# dcan_secure register map
Vendor: Texas Instruments
Registers are 32-bit, access per field, reset 0x0 unless marked. A register's access mark holds for its fields unless they carry their own. Offsets are as the file gives them; [hi:lo] are bit positions; {n}, {i} and the like mark numbered series; 'fields as' and 'values as' point back to an identical list; <NAME> marks a mode.

## dcan_secure (part 2 of 2)
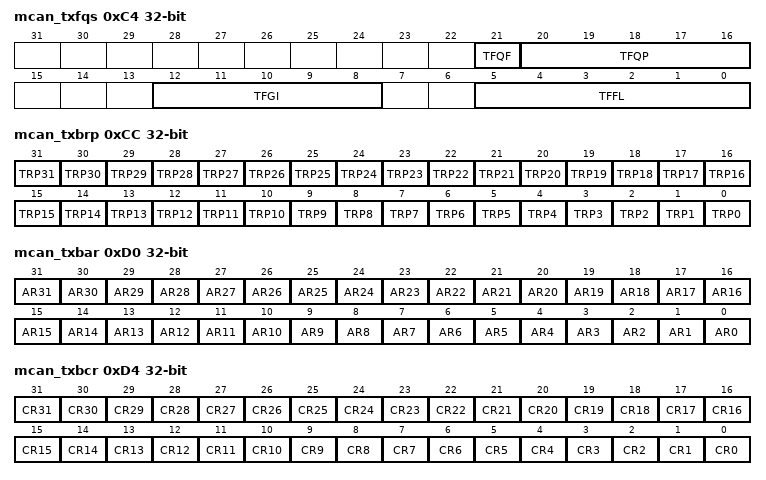
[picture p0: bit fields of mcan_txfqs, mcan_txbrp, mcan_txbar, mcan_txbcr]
0xC4 mcan_txfqs ro — The Tx FIFO/Queue status is related to the pending Tx requests listed in register TXBRP. Therefore the effect of Add/Cancellation requests may be delayed due to a running Tx scan (TXBRP not yet updated).
  [21] TFQF — Tx FIFO/Queue Full 0 Tx FIFO/Queue not full 1 Tx FIFO/Queue full
  [20:16] TFQP — Tx FIFO/Queue Put Index. Tx FIFO/Queue write index pointer, range 0 to 31. Note: In case of mixed configurations where dedicated Tx Buffers are combined with a Tx FIFO or a Tx Queue, the Put and Get Indices indicate the number of the Tx Buffer starting with the first dedicated Tx Buffers. Example: For a configuration of 12 dedicated Tx Buffers and a Tx FIFO of 20 Buffers a Put Index of 15 points to the fourth buffer of the Tx FIFO.
  [12:8] TFGI — Tx FIFO Get Index. Tx FIFO read index pointer, range 0 to 31. Read as zero when Tx Queue operation is configured (TXBC.TFQM = '1'). Note: In case of mixed configurations where dedicated Tx Buffers are combined with a Tx FIFO or a Tx Queue, the Put and Get Indices indicate the number of the Tx Buffer starting with the first dedicated Tx Buffers. Example: For a configuration of 12 dedicated Tx Buffers and a Tx FIFO of 20 Buffers a Put Index of 15 points to the fourth buffer of the Tx FIFO.
  [5:0] TFFL — Tx FIFO Free Level. Number of consecutive free Tx FIFO elements starting from TFGI, range 0 to 32. Read as zero when Tx Queue operation is configured (TXBC.TFQM = '1').
0xC8 mcan_txesc — Configures the number of data bytes belonging to a Tx Buffer element. Data field sizes > 8 bytes are intended for CAN FD operation only.
  [2:0] TBDS rw — Tx Buffer Data Field Size 000 8 byte data field 001 12 byte data field 010 16 byte data field 011 20 byte data field 100 24 byte data field 101 32 byte data field 110 48 byte data field 111 64 byte data field Note: In case the data length code DLC of a Tx Buffer element is configured to a value higher than the Tx Buffer data field size TXESC.TBDS, the bytes not defined by the Tx Buffer are transmitted as "0xCC" (padding bytes). Qualified Write is possible only with CCCR.CCE='1' and CCCR.INIT='1'.
0xCC mcan_txbrp ro — MCAN Tx Buffer Request Pending
  [n] TRP{n} (n=1..31) — Transmission Request Pending {n}. See description for bit 0.
  [0] TRP0 — Transmission Request Pending 0. Each Tx Buffer has its own Transmission Request Pending bit. The bits are set via register TXBAR. The bits are reset after a requested transmission has completed or has been cancelled via register TXBCR. TXBRP bits are set only for those Tx Buffers configured via TXBC. After a TXBRP bit has been set, a Tx scan is started to check for the pending Tx request with the highest priority (Tx Buffer with lowest Message ID). A cancellation request resets the corresponding transmission request pending bit of register TXBRP. In case a transmission has already been started when a cancellation is requested, this is done at the end of the transmission, regardless whether the transmission was successful or not. The cancellation request bits are reset directly after the corresponding TXBRP bit has been reset. After a cancellation has been requested, a finished cancellation is signalled via TXBCF - after successful transmission together with the corresponding TXBTO bit - when the transmission has not yet been started at the point of cancellation - when the transmission has been aborted due to lost arbitration - when an error occurred during frame transmission In DAR mode all transmissions are automatically cancelled if they are not successful. The corresponding TXBCF bit is set for all unsuccessful transmissions. 0 No transmission request pending 1 Transmission request pending Note: TXBRP bits which are set while a Tx scan is in progress are not considered during this particular Tx scan. In case a cancellation is requested for such a Tx Buffer, this Add Request is cancelled immediately, the corresponding TXBRP bit is reset.
0xD0 mcan_txbar rw — MCAN Tx Buffer Add Request
  [n] AR{n} (n=1..31) — Add Request {n}. See description for bit 0.
  [0] AR0 — Add Request 0. Each Tx Buffer has its own Add Request bit. Writing a '1' will set the corresponding Add Request bit; writing a '0' has no impact. This enables the Host to set transmission requests for multiple Tx Buffers with one write to TXBAR. TXBAR bits are set only for those Tx Buffers configured via TXBC. When no Tx scan is running, the bits are reset immediately, else the bits remain set until the Tx scan process has completed. 0 No transmission request added 1 Transmission requested added Note: If an add request is applied for a Tx Buffer with pending transmission request (corresponding TXBRP bit already set), this add request is ignored. Qualified Write is possible only with CCCR.CCE='0'
0xD4 mcan_txbcr rw — MCAN Tx Buffer Cancellation Request
  [n] CR{n} (n=1..31) — Cancellation Request {n}. See description for bit 0.
  [0] CR0 — Cancellation Request 0. Each Tx Buffer has its own Cancellation Request bit. Writing a '1' will set the corresponding Cancellation Request bit; writing a '0' has no impact. This enables the Host to set cancellation requests for multiple Tx Buffers with one write to TXBCR. TXBCR bits are set only for those Tx Buffers configured via TXBC. The bits remain set until the corresponding bit of TXBRP is reset. 0 No cancellation pending 1 Cancellation pending Qualified Write is possible only with CCCR.CCE='0'
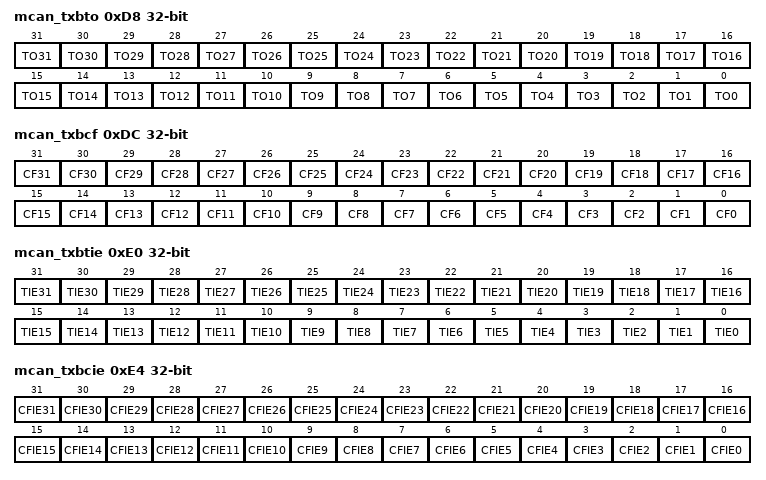
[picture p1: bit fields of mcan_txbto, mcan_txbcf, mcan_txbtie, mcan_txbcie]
0xD8 mcan_txbto ro — MCAN Tx Buffer Transmission Occurred
  [n] TO{n} (n=1..31) — Transmission Occurred {n}. See description for bit 0.
  [0] TO0 — Transmission Occurred 0. Each Tx Buffer has its own Transmission Occurred bit. The bits are set when the corresponding TXBRP bit is cleared after a successful transmission. The bits are reset when a new transmission is requested by writing a '1' to the corresponding bit of register TXBAR. 0 No transmission occurred 1 Transmission occurred
0xDC mcan_txbcf ro — MCAN Tx Buffer Cancellation Finished
  [n] CF{n} (n=1..31) — Cancellation Finished {n}. See description for bit 0.
  [0] CF0 — Cancellation Finished 0. Each Tx Buffer has its own Cancellation Finished bit. The bits are set when the corresponding TXBRP bit is cleared after a cancellation was requested via TXBCR. In case the corresponding TXBRP bit was not set at the point of cancellation, CF is set immediately. The bits are reset when a new transmission is requested by writing a '1' to the corresponding bit of register TXBAR. 0 No transmit buffer cancellation 1 Transmit buffer cancellation finished
0xE0 mcan_txbtie rw — MCAN Tx Buffer Transmission Interrupt Enable
  [n] TIE{n} (n=0..31) — Transmission Interrupt Enable {n}. Each Tx Buffer has its own Transmission Interrupt Enable bit. 0 Transmission interrupt disabled 1 Transmission interrupt enable
0xE4 mcan_txbcie rw — MCAN Tx Buffer Cancellation Finished Interrupt Enable
  [n] CFIE{n} (n=0..31) — Cancellation Finished Interrupt Enable {n}. Each Tx Buffer has its own Cancellation Finished Interrupt Enable bit. 0 Cancellation finished interrupt disabled 1 Cancellation finished interrupt enabled
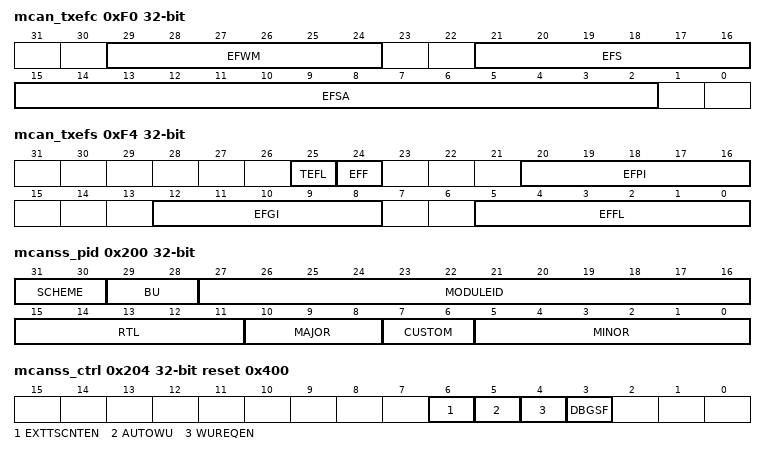
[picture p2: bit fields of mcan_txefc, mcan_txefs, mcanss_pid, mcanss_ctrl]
0xF0 mcan_txefc — MCAN Tx Event FIFO Configuration
  [29:24] EFWM rw — Event FIFO Watermark 0 Watermark interrupt disabled 1-32 Level for Tx Event FIFO watermark interrupt (IR.TEFW) >32 Watermark interrupt disabled
  [21:16] EFS rw — Event FIFO Size. The Tx Event FIFO elements are indexed from 0 to EFS - 1. 0 Tx Event FIFO disabled 1-32 Number of Tx Event FIFO elements >32 Values greater than 32 are interpreted as 32
  [15:2] EFSA rw — Event FIFO Start Address. Start address of Tx Event FIFO in Message RAM (32-bit word address).
0xF4 mcan_txefs ro — MCAN Tx Event FIFO Status
  [25] TEFL — Tx Event FIFO Element Lost. This bit is a copy of interrupt flag IR.TEFL. When IR.TEFL is reset, this bit is also reset. 0 No Tx Event FIFO element lost 1 Tx Event FIFO element lost, also set after write attempt to Tx Event FIFO of size zero.
  [24] EFF — Event FIFO Full 0 Tx Event FIFO not full 1 Tx Event FIFO full
  [20:16] EFPI — Event FIFO Put Index.Tx Event FIFO write index pointer, range 0 to 31.
  [12:8] EFGI — Event FIFO Get Index. Tx Event FIFO read index pointer, range 0 to 31.
  [5:0] EFFL — Event FIFO Fill Level. Number of elements stored in Tx Event FIFO, range 0 to 32.
0xF8 mcan_txefa — MCAN Tx Event FIFO Acknowledge
  [4:0] EFAI rw — Event FIFO Acknowledge Index. After the Host has read an element or a sequence of elements from the Tx Event FIFO it has to write the index of the last element read from Tx Event FIFO to EFAI. This will set the Tx Event FIFO Get Index TXEFS.EFGI to EFAI + 1 and update the Event FIFO Fill Level TXEFS.EFFL.
0x200 mcanss_pid ro reset not defined — MCAN Subsystem Revision Register
  [31:30] SCHEME — PID Register Scheme
  [29:28] BU — Business Unit: 0x2 = Processors
  [27:16] MODULEID — Module Identification Number
  [15:11] RTL — RTL revision. Will vary depending on release
  [10:8] MAJOR — Major Revision of the MCAN Subsystem
  [7:6] CUSTOM — Custom Value
  [5:0] MINOR — Minor Revision of the MCAN Subsystem
0x204 mcanss_ctrl reset 0x400 (reset mask 0xFFFFFF80) — MCAN Subsystem Control Register
  [6] EXTTSCNTEN rw — External Timestamp Counter Enable. 0 External timestamp counter disabled 1 External timestamp counter enabled
  [5] AUTOWU rw — Automatic Wakeup Enable. Enables the MCANSS to automatically clear the MCAN CCCR.INIT bit, fully waking the MCAN up, on an enabled wakeup request. 0 Disable the automatic write to CCCR.INIT 1 Enable the automatic write to CCCR.INIT
  [4] WUREQEN rw — Wakeup Request Enable. Enables the MCANSS to wakeup on CAN RXD activity. 0 Disable wakeup request 1 Enables wakeup request
  [3] DBGSF rw — Debug Suspend Free Bit. Enables debug suspend. 0 Disable debug suspend 1 Enable debug suspend
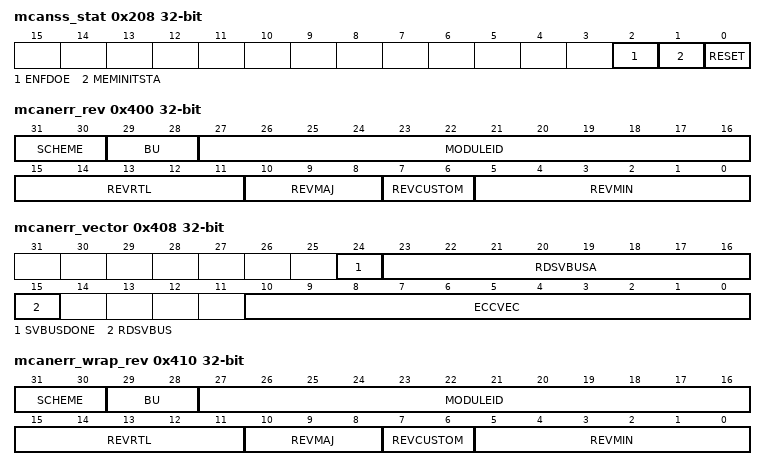
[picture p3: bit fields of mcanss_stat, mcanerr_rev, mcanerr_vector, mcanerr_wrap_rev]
0x208 mcanss_stat ro — MCAN Subsystem Status Register
  [2] ENFDOE — Flexible Datarate Operation Enable. Determines whether CAN FD operation may be enabled via the MCAN core CCCR.FDOE bit (bit 8) or if only standard CAN operation is possible with this instance of the MCAN. 0 MCAN is only capable of standard CAN communication 1 MCAN may be configured to perform CAN FD communication
  [1] MEMINITSTA — Memory Initialization Done. 0 Message RAM initialization is in progress 1 Message RAM is initialized for use
  [0] RESET — Soft Reset Status. 0 Not in reset 1 Reset is in progress
0x20C mcanss_ics — MCAN Subsystem Interrupt Clear Shadow Register
  [0] TSCNTOVFL rw — External Timestamp Counter Overflow Interrupt Status Clear. Reads always return a 0. 0 Write of '0' has no effect 1 Write of '1' clears the MCANSS_IRS.EXT_TS_CNTR_OVFL bit
0x210 mcanss_irs — MCAN Subsystem Interrupt Raw Status Register
  [0] TSCNTOVFL rw — External Timestamp Counter Overflow Interrupt Status. This bit is set by HW or by a SW write of '1'. To clear, use the MCANSS_ICS.EXT_TS_CNTR_OVFL bit. 0 External timestamp counter has not overflowed 1 External timestamp counter has overflowed When this bit is set to '1' by HW or SW, the MCANSS_EXT_TS_UNSERVICED_INTR_CNTR.EXT_TS_INTR_CNTR bit field will increment by 1.
0x214 mcanss_iecs — MCAN Subsystem Interrupt Enable Clear Shadow Register
  [0] TSCNTOVFL rw — External Timestamp Counter Overflow Interrupt Enable Clear. Reads always return a 0. 0 Write of '0' has no effect 1 Write of '1' clears the MCANSS_IES.EXT_TS_CNTR_OVFL bit
0x218 mcanss_ie — MCAN Subsystem Interrupt Enable Register
  [0] TSCNTOVFL rw — External Timestamp Counter Overflow Interrupt Enable. A write of '0' has no effect. A write of '1' sets the MCANSS_IES.EXT_TS_CNTR_OVFL bit.
0x21C mcanss_ies ro — MCAN Subsystem Masked Interrupt Status. It is the logical AND of IRS and IE for the respective bits.
  [0] TSCNTOVFL — External Timestamp Counter Overflow masked interrupt status. 0 External timestamp counter overflow interrupt is cleared 1 External timestamp counter overflow interrupt is set
0x220 mcanss_eoi — MCAN Subsystem End of Interrupt
  [7:0] EOI rw — End of Interrupt. A write to this register will clear the associated interrupt. If the unserviced interrupt counter is > 1, another interrupt is generated. 0x00 External TS Interrupt is cleared 0x01 MCAN(0) interrupt is cleared 0x02 MCAN(1) interrupt is cleared Other writes are ignored.
0x224 mcanss_ext_ts_prescaler — MCAN Subsystem External Timestamp Prescaler 0
  [23:0] PRESCALER rw — External Timestamp Prescaler Reload Value. The external timestamp count rate is the host (system) clock rate divided by this value, except in the case of 0. A zero value in this bit field will act identically to a value of 0x000001.
0x228 mcanss_ext_ts_unserviced_intr_cntr ro — MCAN Subsystem External Timestamp Unserviced Interrupts Counter
  [4:0] INTRCNT — External Timestamp Counter Unserviced Rollover Interrupts. If this value is > 1, an MCANSS_EOI write of '1' to bit 0 will issue another interrupt. The status of this bit field is affected by the MCANSS_IRS.EXT_TS_CNTR_OVFL bit field.
0x400 mcanerr_rev ro reset not defined — MCAN Error Aggregator Revision Register
  [31:30] SCHEME — PID Register Scheme
  [29:28] BU — Business Unit: 0x2 = Processors
  [27:16] MODULEID — Module Identification Number
  [15:11] REVRTL — RTL revision. Will vary depending on release
  [10:8] REVMAJ — Major Revision of the Error Aggregator
  [7:6] REVCUSTOM — Custom Revision of the Error Aggregator
  [5:0] REVMIN — Minor Revision of the Error Aggregator
0x408 mcanerr_vector — Each error detection and correction (EDC) controller has a bank of error registers (offsets 0x10 - 0x3B) associated with it. These registers are accessed via an internal serial bus (SVBUS). To access them through the ECC aggregator the controller ID desired must be written to the ECC_VECTOR field, together with the RD_SVBUS trigger and RD_SVBUS_ADDRESS bit field. This initiates the serial read which consummates by setting the RD_SVBUS_DONE bit. At this point the addressed register may be read by a normal CPU read of the appropriate offset address.
  [24] SVBUSDONE ro — Read Completion Flag
  [23:16] RDSVBUSA rw — Read Address Offset
  [15] RDSVBUS rw — Read Trigger
  [10:0] ECCVEC rw — ECC RAM ID. Each error detection and correction (EDC) controller has a bank of error registers (offsets 0x10 - 0x3B) associated with it. These registers are accessed via an internal serial bus (SVBUS). To access them through the ECC aggregator the controller ID desired must be written to the ECC_VECTOR field, together with the RD_SVBUS trigger and RD_SVBUS_ADDRESS bit field. This initiates the serial read which consummates by setting the RD_SVBUS_DONE bit. At this point the addressed register may be read by a normal CPU read of the appropriate offset address. 0x000 Message RAM ECC controller is selected Others Reserved (do not use) Subsequent writes through the SVBUS (offsets 0x10 - 0x3B) have a delayed completion. To avoid conflicts, perform a read back of a register within this range after writing.
0x40C mcanerr_stat ro reset 0x1002 — MCAN Error Misc Status
  [10:0] NUMRAMS — Number of RAMs. Number of ECC RAMs serviced by the aggregator.
0x410 mcanerr_wrap_rev ro reset not defined — This register is accessed through the ECC aggregator via an internal serial bus. To access, the appropriate procedure must be first followed in the MCAN ECC Vector Register.
  fields as mcanerr_rev
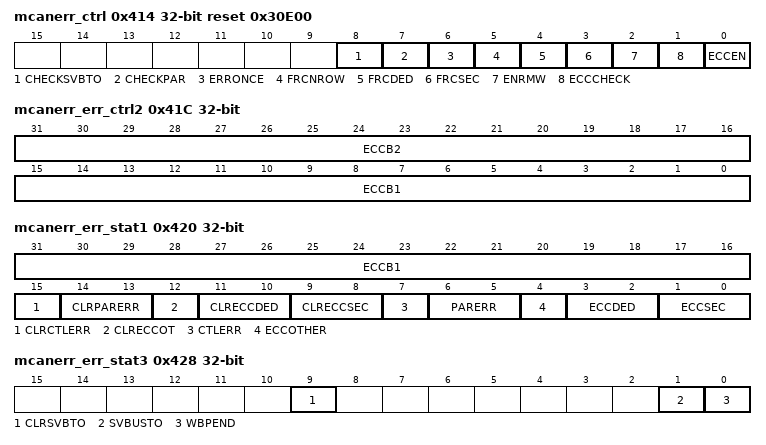
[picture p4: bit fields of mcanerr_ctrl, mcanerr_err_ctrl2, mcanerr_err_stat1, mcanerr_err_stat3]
0x414 mcanerr_ctrl reset 0x30E00 (reset mask 0xFFFFFE00) — This register is accessed through the ECC aggregator via an internal serial bus. To access, the appropriate procedure must be first followed in the MCAN ECC Vector Register.
  [8] CHECKSVBTO rw — Enables Serial VBUS timeout mechanism
  [7] CHECKPAR rw — Enables parity checking on internal data
  [6] ERRONCE rw — If this bit is set, the FORCE_SEC/FORCE_DED will inject an error to the specified row only once. The FORCE_SEC bit will be cleared once a writeback happens. If writeback is not enabled, this error will be cleared the cycle following the read when the data is corrected. For double-bit errors, the FORCE_DED bit will be cleared the cycle following the double-bit error. Any subsequent reads will not force an error.
  [5] FRCNROW rw — Enable single/double-bit error on the next RAM read, regardless of the MCANERR_ERR_CTRL1.ECC_ROW setting. For write through mode, this applies to writes as well as reads.
  [4] FRCDED rw — Force double-bit error. Cleared the cycle following the error if ERROR_ONCE is asserted. For write through mode, this applies to writes as well as reads. MCANERR_ERR_CTRL1 and MCANERR_ERR_CTRL2 should be configured prior to setting this bit.
  [3] FRCSEC rw — Force single-bit error. Cleared on a writeback or the cycle following the error if ERROR_ONCE is asserted. For write through mode, this applies to writes as well as reads. MCANERR_ERR_CTRL1 and MCANERR_ERR_CTRL2 should be configured prior to setting this bit.
  [2] ENRMW rw — Enable read-modify-write on partial word writes
  [1] ECCCHECK rw — Enable ECC Check. ECC is completely bypassed if both ECC_ENABLE and ECC_CHECK are '0'.
  [0] ECCEN rw — Enable ECC Generation
0x418 mcanerr_err_ctrl1 rw — This register is accessed through the ECC aggregator via an internal serial bus. To access, the appropriate procedure must be first followed in the MCAN ECC Vector Register.
  [31:0] ECCROW — Row address where FORCE_SEC or FORCE_DED needs to be applied. This is ignored if FORCE_N_ROW is set.
0x41C mcanerr_err_ctrl2 rw — This register is accessed through the ECC aggregator via an internal serial bus. To access, the appropriate procedure must be first followed in the MCAN ECC Vector Register.
  [31:16] ECCB2 — Second column/data bit that needs to be flipped when FORCE_DED is set
  [15:0] ECCB1 — Column/Data bit that needs to be flipped when FORCE_SEC or FORCE_DED is set
0x420 mcanerr_err_stat1 — This register is accessed through the ECC aggregator via an internal serial bus. To access, the appropriate procedure must be first followed in the MCAN ECC Vector Register.
  [31:16] ECCB1 ro — ECC Error Bit Position. Indicates the bit position in the RAM data that is in error on an SEC error. Only valid on an SEC error. 0 Bit 0 is in error 1 Bit 1 is in error 2 Bit 2 is in error 3 Bit 3 is in error ... 31 Bit 31 is in error >32 Invalid
  [15] CLRCTLERR rw — Writing a '1' clears the CTRL_REG_ERROR bit
  [14:13] CLRPARERR rw — Clear Parity Error. A write of a non-zero value to this bit field decrements the PARITY_ERROR bit field by the value provided.
  [12] CLRECCOT rw — Writing a '1' clears the ECC_OTHER bit.
  [11:10] CLRECCDED rw — Clear ECC_DED. A write of a non-zero value to this bit field decrements the ECC_DED bit field by the value provided.
  [9:8] CLRECCSEC rw — Clear ECC_SEC. A write of a non-zero value to this bit field decrements the ECC_SEC bit field by the value provided.
  [7] CTLERR rw — Control Register Error. A bit field in the control register is in an ambiguous state. This means that the redundancy registers have detected a state where not all values are the same and has defaulted to the reset state. S/W needs to re-write these registers to a known state. A write of 1 will set this interrupt flag.
  [6:5] PARERR rw — Parity Error Status. A 2-bit saturating counter of the number of parity errors that have occurred since last cleared. 0 No parity error detected 1 One parity error was detected 2 Two parity errors were detected 3 Three parity errors were detected A write of a non-zero value to this bit field increments it by the value provided.
  [4] ECCOTHER rw — SEC While Writeback Error Status 0 No SEC error while writeback pending 1 Indicates that successive single-bit errors have occurred while a writeback is still pending
  [3:2] ECCDED rw — Double Bit Error Detected Status. A 2-bit saturating counter of the number of DED errors that have occurred since last cleared. 0 No double-bit error detected 1 One double-bit error was detected 2 Two double-bit errors were detected 3 Three double-bit errors were detected A write of a non-zero value to this bit field increments it by the value provided.
  [1:0] ECCSEC rw — Single Bit Error Corrected Status. A 2-bit saturating counter of the number of SEC errors that have occurred since last cleared. 0 No single-bit error detected 1 One single-bit error was detected and corrected 2 Two single-bit errors were detected and corrected 3 Three single-bit errors were detected and corrected A write of a non-zero value to this bit field increments it by the value provided.
0x424 mcanerr_err_stat2 ro — This register is accessed through the ECC aggregator via an internal serial bus. To access, the appropriate procedure must be first followed in the MCAN ECC Vector Register.
  [31:0] ECCROW — Indicates the row address where the single or double-bit error occurred. This value is address offset/4.
0x428 mcanerr_err_stat3 — This register is accessed through the ECC aggregator via an internal serial bus. To access, the appropriate procedure must be first followed in the MCAN ECC Vector Register.
  [9] CLRSVBTO rw — Write 1 to clear the Serial VBUS Timeout Flag
  [1] SVBUSTO rw — Serial VBUS Timeout Flag. Write 1 to set.
  [0] WBPEND ro — Delayed Write Back Pending Status 0 No write back pending 1 An ECC data correction write back is pending
0x43C mcanerr_sec_eoi — MCAN Single Error Corrected End of Interrupt Register
  [0] EOIWR rw — Write to this register indicates that software has acknowledged the pending interrupt and the next interrupt can be sent to the host. Note that a write to the MCANERR_ERR_STAT1.CLR_ECC_SEC goes through the SVBUS and has a delayed completion. To avoid an additional interrupt, read the MCANERR_ERR_STAT1 register back prior to writing to this bit field.
0x440 mcanerr_sec_status — MCAN Single Error Corrected Interrupt Status Register
  [0] MGSPEND rw — Message RAM SEC Interrupt Pending 0 No SEC interrupt is pending 1 SEC interrupt is pending
0x480 mcanerr_sec_enable_set — MCAN Single Error Corrected Interrupt Enable Set Register
  [0] MSGENSET rw — Message RAM SEC Interrupt Pending Enable Set. Writing a 1 to this bit enables the Message RAM SEC error interrupts. Writing a 0 has no effect. Reads return the corresponding enable bit's current value.
0x4C0 mcanerr_sec_enable_clr — MCAN Single Error Corrected Interrupt Enable Clear Register
  [0] MSGENCLR rw — Message RAM SEC Interrupt Pending Enable Clear. Writing a 1 to this bit disables the Message RAM SEC error interrupts. Writing a 0 has no effect. Reads return the corresponding enable bit's current value.
0x53C mcanerr_ded_eoi — MCAN Double Error Detected End of Interrupt Register
  [0] EOIWR rw — Write to this register indicates that software has acknowledged the pending interrupt and the next interrupt can be sent to the host. Note that a write to the MCANERR_ERR_STAT1.CLR_ECC_DED goes through the SVBUS and has a delayed completion. To avoid an additional interrupt, read the MCANERR_ERR_STAT1 register back prior to writing to this bit field.
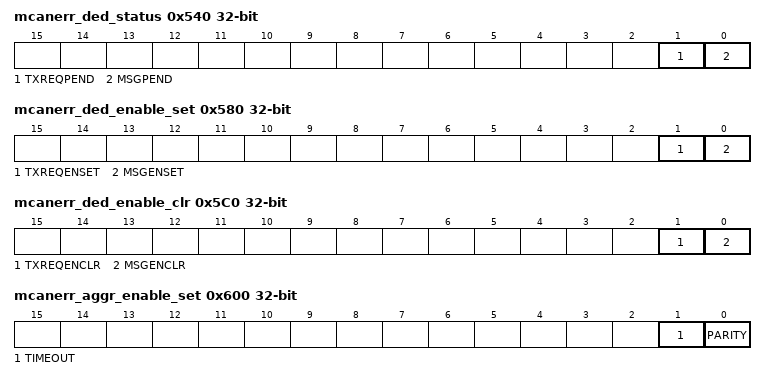
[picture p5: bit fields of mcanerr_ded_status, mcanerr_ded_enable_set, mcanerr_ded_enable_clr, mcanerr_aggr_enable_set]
0x540 mcanerr_ded_status — MCAN Double Error Detected Interrupt Status Register
  [1] TXREQPEND rw — TX Empty DMA Request Parity Interrupt Pending 0 No parity error interrupt is pending 1 A parity error interrupt is pending
  [0] MSGPEND rw — Message RAM DED Interrupt Pending 0 No DED interrupt is pending 1 DED interrupt is pending
0x580 mcanerr_ded_enable_set — MCAN Double Error Detected Interrupt Enable Set Register
  [1] TXREQENSET rw — TX Empty DMA Request Parity Interrupt Pending Enable Set. Writing a 1 to this bit enables the TX empty DMA request parity error interrupts. Writing a 0 has no effect. Reads return the corresponding enable bit's current value.
  [0] MSGENSET rw — Message RAM DED Interrupt Pending Enable Set. Writing a 1 to this bit enables the Message RAM DED error interrupts. Writing a 0 has no effect. Reads return the corresponding enable bit's current value.
0x5C0 mcanerr_ded_enable_clr — MCAN Double Error Detected Interrupt Enable Clear Register
  [1] TXREQENCLR rw — TX Empty DMA Request Parity Interrupt Pending Enable Clear. Writing a 1 to this bit disables the TX empty DMA request parity error interrupts. Writing a 0 has no effect. Reads return the corresponding enable bit's current value.
  [0] MSGENCLR rw — Message RAM DED Interrupt Pending Enable Clear. Writing a 1 to this bit disables the Message RAM DED error interrupts. Writing a 0 has no effect. Reads return the corresponding enable bit's current value.
0x600 mcanerr_aggr_enable_set — MCAN Error Aggregator Enable Set Register
  [1] TIMEOUT rw — Write 1 to enable timeout errors. Reads return the corresponding enable bit's current value.
  [0] PARITY rw — Write 1 to enable parity errors. Reads return the corresponding enable bit's current value.
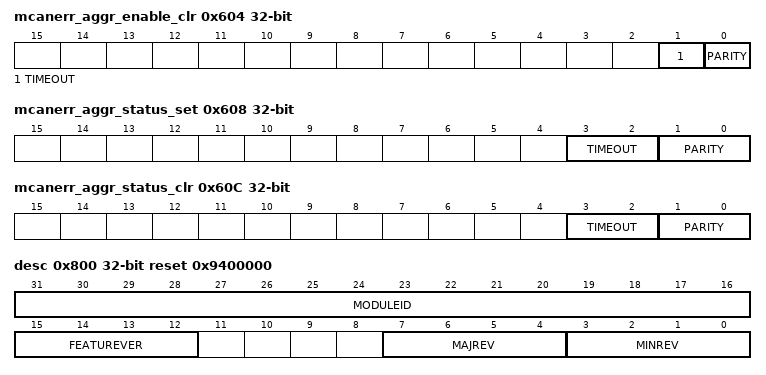
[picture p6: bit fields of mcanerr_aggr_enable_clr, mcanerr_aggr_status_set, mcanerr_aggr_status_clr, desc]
0x604 mcanerr_aggr_enable_clr — MCAN Error Aggregator Enable Clear Register
  [1] TIMEOUT rw — Write 1 to disable timeout errors. Reads return the corresponding enable bit's current value.
  [0] PARITY rw — Write 1 to disable parity errors. Reads return the corresponding enable bit's current value.
0x608 mcanerr_aggr_status_set — MCAN Error Aggregator Status Set Register
  [3:2] TIMEOUT rw — Aggregator Serial VBUS Timeout Error Status 2-bit saturating counter of the number of SVBUS timeout errors that have occurred since last cleared. 0 No timeout errors have occurred 1 One timeout error has occurred 2 Two timeout errors have occurred 3 Three timeout errors have occurred A write of a non-zero value to this bit field increments it by the value provided.
  [1:0] PARITY rw — Aggregator Parity Error Status 2-bit saturating counter of the number of parity errors that have occurred since last cleared. 0 No parity errors have occurred 1 One parity error has occurred 2 Two parity errors have occurred 3 Three parity errors have occurred A write of a non-zero value to this bit field increments it by the value provided.
0x60C mcanerr_aggr_status_clr — MCAN Error Aggregator Status Clear Register
  [3:2] TIMEOUT rw — Aggregator Serial VBUS Timeout Error Status 2-bit saturating counter of the number of SVBUS timeout errors that have occurred since last cleared. 0 No timeout errors have occurred 1 One timeout error has occurred 2 Two timeout errors have occurred 3 Three timeout errors have occurred A write of a non-zero value to this bit field decrements it by the value provided.
  [1:0] PARITY rw — Aggregator Parity Error Status 2-bit saturating counter of the number of parity errors that have occurred since last cleared. 0 No parity errors have occurred 1 One parity error has occurred 2 Two parity errors have occurred 3 Three parity errors have occurred A write of a non-zero value to this bit field decrements it by the value provided.
0x800 desc ro reset 0x9400000 — This register identifies the peripheral and its exact version.
  [31:16] MODULEID — Module identification contains a unique peripheral identification number. The assignments are maintained in a central database for all of the platform modules to ensure uniqueness.
    0=MINIMUM (Smallest value); 0xFFFF=MAXIMUM (Highest possible value)
  [15:12] FEATUREVER — Feature Set for the module *instance*
    0=VERSION_0 (MCAN module with CAN-FD mode enabled <<Internal Note: This is an in-IP paper spin variant. How does this map to the SYS_MCAN_ENABLE_FD choice value?>>); 1=VERSION_1 (MCAN module with CAN-FD mode disabled <<Internal Note: This is an in-IP paper spin variant. How does this map to the SYS_MCAN_ENABLE_FD choice value?>>)
  [7:4] MAJREV — Major rev of the IP
    0=MINIMUM (Smallest value); 15=MAXIMUM (Highest possible value)
  [3:0] MINREV — Minor rev of the IP
    values as MAJREV
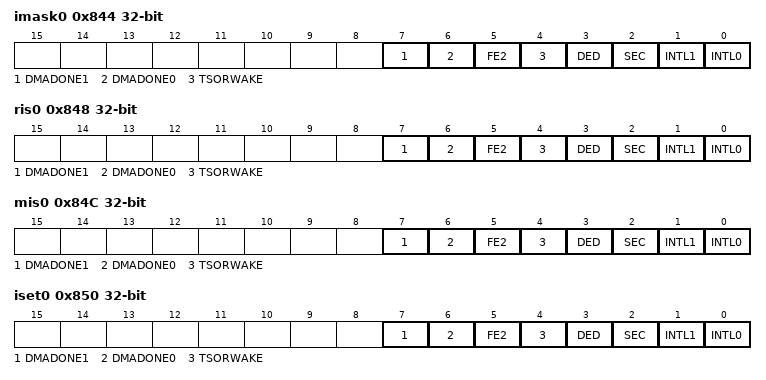
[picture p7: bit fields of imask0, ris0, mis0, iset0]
0x844 imask0 — Interrupt Mask. If a bit is set, then corresponding interrupt is un-masked. Un-masking the interrupt causes the raw interrupt to be visible in IIDX, as well as MIS.
  [7] DMADONE1 rw — Mask Channel1 Event.
    0=CLR (Clear Interrupt Mask); 1=SET (Set Interrrupt Mask)
  [6] DMADONE0 rw — Mask Channel1 Event.
    0=CLR (Clear Interrupt Mask); 1=SET (Set Interrrupt Mask)
  [5] FE2 rw — Mask Channel1 Event.
    0=CLR (Clear Interrupt Mask); 1=SET (Set Interrrupt Mask)
  [4] TSORWAKE rw — Mask Channel1 Event.
    0=CLR (Clear Interrupt Mask); 1=SET (Set Interrrupt Mask)
  [3] DED rw — Mask Channel1 Event.
    0=CLR (Clear Interrupt Mask); 1=SET (Set Interrrupt Mask)
  [2] SEC rw — Mask Channel1 Event.
    0=CLR (Clear Interrupt Mask); 1=SET (Set Interrrupt Mask)
  [1] INTL1 rw — Mask Channel1 Event.
    0=CLR (Clear Interrupt Mask); 1=SET (Set Interrrupt Mask)
  [0] INTL0 rw — Mask channel0 Event
    0=CLR (Clear Interrupt Mask); 1=SET (Set Interrupt Mask)
0x848 ris0 ro — Raw interrupt status. Reflects all pending interrupts, regardless of masking. The RIS0 register allows the user to implement a poll scheme. A flag set in this register can be cleared by writing 1 to the ICLR register bit even if the corresponding IMASK bit is not enabled.
  [all] fields
    0=CLR (Interrupt did not occur); 1=SET (Interrupt occured)
  [7] DMADONE1 — Raw interrupt status for EVENT0. This bit is set to 1 when an event is received on EVENT0 channel. when the corresponding bit in ICLR is set to 1, this bit will be cleared. This bit is also cleared when a new compare value is written in CH0CMP register
  [6] DMADONE0 — Raw interrupt status for EVENT0. This bit is set to 1 when an event is received on EVENT0 channel. when the corresponding bit in ICLR is set to 1, this bit will be cleared. This bit is also cleared when a new compare value is written in CH0CMP register
  [5] FE2 — Raw interrupt status for EVENT0. This bit is set to 1 when an event is received on EVENT0 channel. when the corresponding bit in ICLR is set to 1, this bit will be cleared. This bit is also cleared when a new compare value is written in CH0CMP register
  [4] TSORWAKE — Raw interrupt status for EVENT0. This bit is set to 1 when an event is received on EVENT0 channel. when the corresponding bit in ICLR is set to 1, this bit will be cleared. This bit is also cleared when a new compare value is written in CH0CMP register
  [3] DED — Raw interrupt status for EVENT0. This bit is set to 1 when an event is received on EVENT0 channel. when the corresponding bit in ICLR is set to 1, this bit will be cleared. This bit is also cleared when a new compare value is written in CH0CMP register
  [2] SEC — Raw interrupt status for EVENT0. This bit is set to 1 when an event is received on EVENT0 channel. when the corresponding bit in ICLR is set to 1, this bit will be cleared. This bit is also cleared when a new compare value is written in CH0CMP register
  [1] INTL1 — Raw interrupt status for EVENT1. This bit is set to 1 when an event is received on EVENT1 channel. when the corresponding bit in ICLR is set to 1, this bit will be cleared. This bit is also cleared when the captured time value is read from the CH1CAPT register.
  [0] INTL0 — Raw interrupt status for EVENT0. This bit is set to 1 when an event is received on EVENT0 channel. when the corresponding bit in ICLR is set to 1, this bit will be cleared. This bit is also cleared when a new compare value is written in CH0CMP register
0x84C mis0 ro — Masked interrupt status. This is an AND of the IMASK and RIS registers.
  [all] fields
    0=CLR (Interrupt did not occur); 1=SET (Interrupt occured)
  [7] DMADONE1 — Mask interrupt status for EVENT0
  [6] DMADONE0 — Mask interrupt status for EVENT0
  [5] FE2 — Mask interrupt status for EVENT0
  [4] TSORWAKE — Mask interrupt status for EVENT0
  [3] DED — Mask interrupt status for EVENT0
  [2] SEC — Mask interrupt status for EVENT0
  [1] INTL1 — Mask interrupt status for EVENT1
  [0] INTL0 — Mask interrupt status for EVENT0
0x850 iset0 — Interrupt set. Allows interrupts to be set by software (useful in diagnostics and safety checks). Writing a 1 to a bit in ISET0 will set the event and therefore the related RIS bit also gets set. If the interrupt is enabled through the mask, then the corresponding MIS bit is also set.
  [all] fields
    0=NO_EFFECT (Writing 0 has no effect); 1=SET (Sets interrupt)
  [7] DMADONE1 wo — Sets EVENT0 in RIS
  [6] DMADONE0 wo — Sets EVENT0 in RIS
  [5] FE2 wo — Sets EVENT0 in RIS
  [4] TSORWAKE wo — Sets EVENT0 in RIS
  [3] DED wo — Sets EVENT0 in RIS
  [2] SEC wo — Sets EVENT0 in RIS
  [1] INTL1 wo — Sets EVENT1 in RIS
  [0] INTL0 wo — Sets EVENT0 in RIS
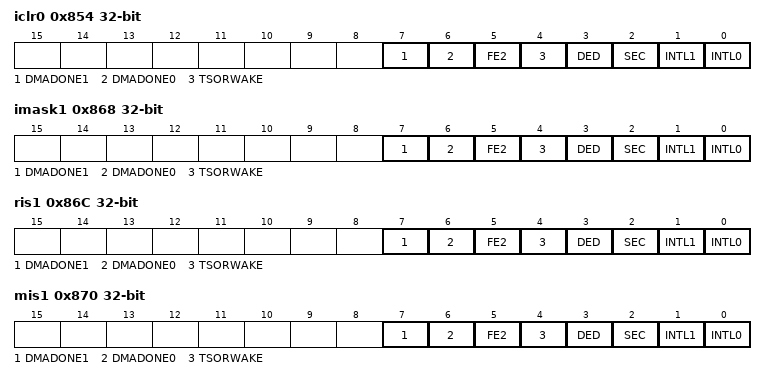
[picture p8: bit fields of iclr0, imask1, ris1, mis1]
0x854 iclr0 — Interrupt clear. Write a 1 to clear corresponding Interrupt.
  [all] fields
    0=NO_EFFECT (Writing 0 has no effect); 1=CLR (Clears the Event)
  [7] DMADONE1 wo — Clears EVENT0 in RIS
  [6] DMADONE0 wo — Clears EVENT0 in RIS
  [5] FE2 wo — Clears EVENT0 in RIS
  [4] TSORWAKE wo — Clears EVENT0 in RIS
  [3] DED wo — Clears EVENT0 in RIS
  [2] SEC wo — Clears EVENT0 in RIS
  [1] INTL1 wo — Clears EVENT1 in RIS
  [0] INTL0 wo — Clears EVENT0 in RIS
0x868 imask1 — Interrupt Mask. If a bit is set, then corresponding interrupt is un-masked. Un-masking the interrupt causes the raw interrupt to be visible in IIDX, as well as MIS.
  [all] fields
    0=CLR (Clear Interrupt Mask); 1=SET (Set Interrrupt Mask)
  [7] DMADONE1 rw — Mask Channel1 Event.
  [6] DMADONE0 rw — Mask Channel1 Event.
  [5] FE2 rw — Mask Channel1 Event.
  [4] TSORWAKE rw — Mask Channel1 Event.
  [3] DED rw — Mask Channel1 Event.
  [2] SEC rw — Mask Channel1 Event.
  [1] INTL1 rw — Mask Channel1 Event.
  [0] INTL0 rw — Mask channel0 Event
0x86C ris1 ro — Raw interrupt status. Reflects all pending interrupts, regardless of masking. The RIS0 register allows the user to implement a poll scheme. A flag set in this register can be cleared by writing 1 to the ICLR register bit even if the corresponding IMASK bit is not enabled.
  fields as ris0
0x870 mis1 ro — Masked interrupt status. This is an AND of the IMASK and RIS registers.
  fields as mis0
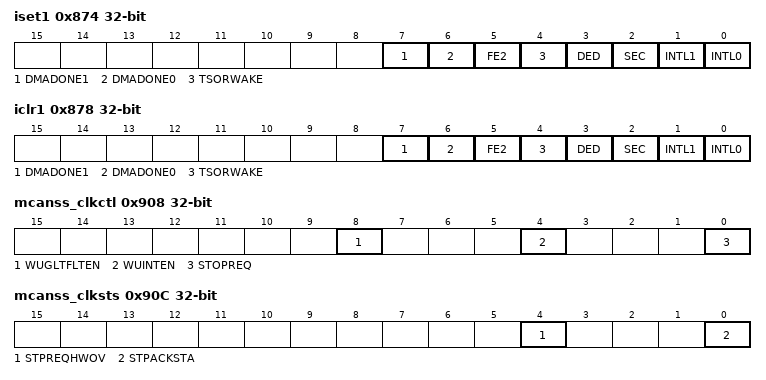
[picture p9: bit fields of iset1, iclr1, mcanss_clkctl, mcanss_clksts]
0x874 iset1 — Interrupt set. Allows interrupts to be set by software (useful in diagnostics and safety checks). Writing a 1 to a bit in ISET0 will set the event and therefore the related RIS bit also gets set. If the interrupt is enabled through the mask, then the corresponding MIS bit is also set.
  fields as iset0
0x878 iclr1 — Interrupt clear. Write a 1 to clear corresponding Interrupt.
  fields as iclr0
0x904 mcanss_clkdiv — Needs to go to the Management aperture once available
  [1:0] RATIO rw — Clock divide ratio specification. Enables configuring clock divide settings for the MCAN functional clock input to the MCAN-SS.
    0=DIV_BY_1_ (Divides input clock by 1); 1=DIV_BY_2_ (Divides input clock by 2); 2=DIV_BY_4_ (Divides input clock by 4)
0x908 mcanss_clkctl — MCANSS clock stop control MMR. <Internal note> Bus clock for the Dragon wrapper MMRs (including this MMR) is not gated by this register.
  [8] WUGLTFLTEN rw — Setting this bit enables the glitch filter on MCAN RXD input, which wakes up the MCAN controller to exit clock gating.
    0=DISABLE (Disable glitch filter enable on RXD input when MCAN is in clock stop mode (waiting for event on RXD input for clock stop wakeup).); 1=ENABLE (Enable glitch filter enable on RXD input when MCAN is in clock stop mode (waiting for event on RXD input for clock stop wakeup).)
  [4] WUINTEN rw — This bit controls enabling or disabling the MCAN IP clock stop wakeup interrupt (when MCANSS_CTRL.WAKEUPREQEN wakeup request is enabled to wakeup MCAN IP upon CAN RXD activity)
    1=ENABLE (Enable MCAN IP clock stop wakeup interrupt); 0=DISABLE (Disable MCAN IP clock stop wakeup interrupt)
  [0] STOPREQ rw — This bit is used to enable/disable MCAN clock (both host clock and functional clock) gating request. Note: This bit can be reset by HW by Clock-Stop Wake-up via CAN RX Activity. See spec for more details.
    0=DISABLE (Disable MCAN-SS clock stop request); 1=ENABLE (Enable MCAN-SS clock stop request)
0x90C mcanss_clksts ro — MCANSS clock stop status register to indicate status of clock stop mechanism
  [4] STPREQHWOV — MCANSS clock stop HW override status bit. This bit indicates when the MCANSS_CLKCTL.STOPREQ bit has been cleared by HW when a clock-stop wake-up event via CAN RX activity is triggered.
    0=RESET (MCANSS_CLKCTL.STOPREQ bit has not been cleared by HW.); 1=SET (MCANSS_CLKCTL.STOPREQ bit has been cleared by HW.)
  [0] STPACKSTA — Clock stop acknowledge status from MCAN IP
    0=RESET (No clock stop acknowledged.); 1=SET (MCAN-SS may be clock gated by stopping both the CAN host and functional clocks.)
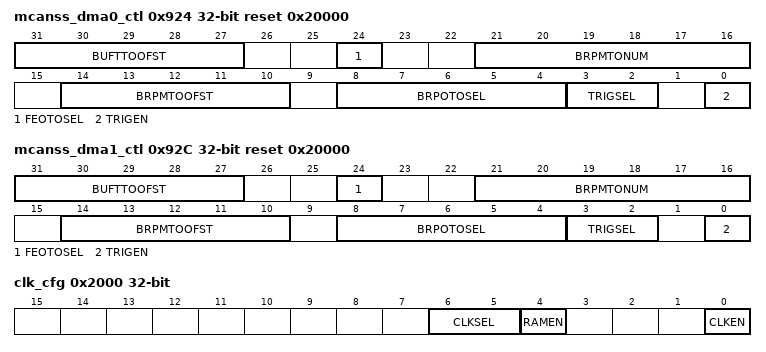
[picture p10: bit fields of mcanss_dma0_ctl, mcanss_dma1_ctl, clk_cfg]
0x924 mcanss_dma0_ctl reset 0x20000 — MCANSS fixed DMA0 control and configuration register
  [31:27] BUFTTOOFST rw — Indicates the Rx-buffer (index x) to be mapped to FE_0 (FE001) and automatically maps and Rx buffer (index x+1) to FE_1 (FE010) Valid range: Rxbuffer (0) to Rxbuffer (30)
    0=MIN (Minimum index value: 0); 30=MAX (Maximum index value: 30 Note: RX_FE_TTO_SEL Rx buffer index selection for FE01 cannot be 31, as Rxbuffer (index +1) maps to 32, which requires updating NDAT1 and NDAT2 value, which is not supported.)
  [24] FEOTOSEL rw — RX_FE_OTO_SEL is used to select the MCAN RX buffer filter event signal mapped to trigger fixed MCANSS DMA channel trigger
    0=FE_0 (Filter Event 0); 1=FE_1 (Filter Event 1)
  [21:16] BRPMTONUM rw — Number of TX buffer request pending (BRP) signals for multi-to-one DMA trigger mapping sequence, starting from the buffer offset number selected by TX_BRP_MTO_OFFST bits
    2=MIN (Min number for TX BRP multi-to-one DMA trigger mapping sequence is 2); 32=MAX (Max number for TX BRP multi-to-one DMA trigger mapping sequence is 32)
  [14:10] BRPMTOOFST rw — TX_BRP_MTO_OFFST selects the Tx buffer offset number for the multi-to-one round robin DMA trigger mode.
    {v}=TX_BRP_{v} (TX Buffer Request Pending {v}) (v=0..31)
  [8:4] BRPOTOSEL rw — TX_BRP_OTO_SEL is used to select the MCAN TX buffer request pending (BRP) signal mapped to trigger fixed MCANSS DMA channel trigger
    {v}=TX_BRP_{v} (TX Buffer Request Pending {v}) (v=0..31)
  [3:2] TRIGSEL rw — DMA trigger select bits used to select between MCAN TX one-to-one mapping, MCAN TX multi-to-one round robin mapping and MCAN Rx one-to-one mapping options
    0=TX_OTO_TRIG (MCAN TX Buffer one-to-one Tx BRP (buffer request pending) trigger to DMA channel select); 2=RX_OTO_TRIG (MCAN RX Buffer one-to-one Tx BRP (buffer request pending) trigger to DMA channel select); 1=TX_MTO_TRIG (MCAN TX Buffer multi-to-one round robin, Tx BRP (buffer request pending) triggers to DMA channel select); 3=RX_TTO_TRIG (Rx buffer two-to-one DMA trigger)
  [0] TRIGEN rw — DMA_TRIG_EN is used to enable/disable MCAN RX, TX triggers to MCANSS fixed DMA channel. <Note to design> check if this bit is needed depending on if similar functionality is enabled in the EXT_DMA aperture.
    0=DISABLE (MCANSS fixed DMA channel trigger is disabled.); 1=ENABLE (MCANSS fixed DMA channel trigger is enabled.)
0x92C mcanss_dma1_ctl reset 0x20000 — MCANSS fixed DMA1 control and configuration register
  [31:27] BUFTTOOFST rw — Indicates the Rx-buffer (index x) to be mapped to FE_0 (FE001) and automatically maps and Rx buffer (index x+1) to FE_1 (FE010) Valid range: Rxbuffer (0) to Rxbuffer (30)
    values as mcanss_dma0_ctl.BUFTTOOFST
  [24] FEOTOSEL rw — RX_FE_OTO_SEL is used to select the MCAN RX buffer filter event signal mapped to trigger fixed MCANSS DMA channel trigger
    0=FE_0 (Filter Event 0); 1=FE_1 (Filter Event 1)
  [21:16] BRPMTONUM rw — Number of TX buffer request pending (BRP) signals for multi-to-one DMA trigger mapping sequence, starting from the buffer offset number selected by TX_BRP_MTO_OFFST bits
    values as mcanss_dma0_ctl.BRPMTONUM
  [14:10] BRPMTOOFST rw — TX_BRP_MTO_OFFST selects the Tx buffer offset number for the multi-to-one round robin DMA trigger mode.
    {v}=TX_BRP_{v} (TX Buffer Request Pending {v}) (v=0..31)
  [8:4] BRPOTOSEL rw — TX_BRP_OTO_SEL is used to select the MCAN TX buffer request pending (BRP) signal mapped to trigger fixed MCANSS DMA channel trigger
    {v}=TX_BRP_{v} (TX Buffer Request Pending {v}) (v=0..31)
  [3:2] TRIGSEL rw — DMA trigger select bits used to select between MCAN TX one-to-one mapping, MCAN TX multi-to-one round robin mapping and MCAN Rx one-to-one mapping options
    0=TX_OTO_TRIG (MCAN TX Buffer one-to-one Tx BRP (buffer request pending) trigger to DMA channel select); 2=RX_OTO_TRIG (MCAN RX Buffer one-to-one Tx BRP (buffer request pending) trigger to DMA channel select); 1=TX_MTO_TRIG (MCAN TX Buffer multi-to-one round robin Tx BRP (buffer request pending) triggers to DMA channel select); 3=RX_TTO_TRIG (Rx buffer two-to-one DMA trigger)
  [0] TRIGEN rw — DMA_TRIG_EN is used to enable/disable MCAN RX, TX triggers to MCANSS fixed DMA channel. <Note to design> check if this bit is needed depending on if similar functionality is enabled in the EXT_DMA aperture.
    values as mcanss_dma0_ctl.TRIGEN
0x938 rxdma_tto_fe0_ba — Rx buffer (index x) base address. <Internal: Absolute address within MCAN IP: 0x7938> Applicable to Rx buffer DMA two-to-one mode mapped to FE001 trigger: >> LS bits 0:1 in this MMR are reserved and read as '0' as the MCAN SRAM is 4 byte data addressable. >> Index x is selected using MCANSS_DMAn_CTL.RX_FE_TTO_SEL bits.
  [14:2] BASEADDR rw — FE0 Rx Buf x Base address (14:2). Address should be computed based on the 14-bit RBSA (Rx buffer start address) + offset (depending on Rx buffer element index value and data length code (DLC) for all the buffer elements before the Rx buffer element (x))
    0=MIN (Min address offset within MCANSS SRAM: 0x0); 0x1FFF=MAX (Max address offset within MCANSS SRAM: 0x1fff)
0x948 rxdma_tto_fe1_ba — Rx buffer (index x+1) base address <Internal: Absolute address within MCAN IP: 0x7948> Applicable to Rx buffer DMA two-to-one mode mapped to FE010 trigger: >> LS bits 0:1 in this MMR are reserved and read as '0' as the MCAN SRAM is 4 byte data addressable. >> Index x is selected using MCANSS_DMAn_CTL.RX_FE_TTO_SEL bits.
  [14:2] BASEADDR rw — FE010 Rx Buf x Base adddress (14:2). Address should be compited based on the 14-bit RBSA (Rx buffer start address) + offset (depending on Rx buffer element index value and data length code (DLC) for all the buffer elements before the Rx buffer element (x+1))
    values as rxdma_tto_fe0_ba.BASEADDR
0x950 rxdma_tto_ndat1 ro — Rx Buffer two-to-one DMA mode, hardware NDAT1 value register. The address of this register is programmed as the DMA source address register for moving NDAT1 value during DMA operation. This register is automatically updated on the fly depending on FE001/FE010 (Rxbuf(x)/Rxbuf(x+1)) ongoing transfer.
  [31:0] NDAT1VAL — NDAT1 value to be programmed onto MCAN.NDAT1 MMR. Automatically updated by HW.
    0=MIN (Min value = 0x0 (not bits set)); 0x80000000=MAX (max value = (bit 31 set) = 0x80000000)
0x2000 clk_cfg — Clock Configuration MMR for **DCAN**
  [6:5] CLKSEL rw — DCAN clock selection
    0=No clock is selected; 1=host_div2_clk (80Mhz host clock is selected.); 2=HFXT (HFXT is selected as source); 3=host_div2_pswl_clk (Un-swallowed clock 80Mhz is selected.)
  [4] RAMEN rw — Ram Enable Paper spin option.
  [0] CLKEN rw — 0: **DCAN** clock disabled 1: **DCAN** clock enabled
